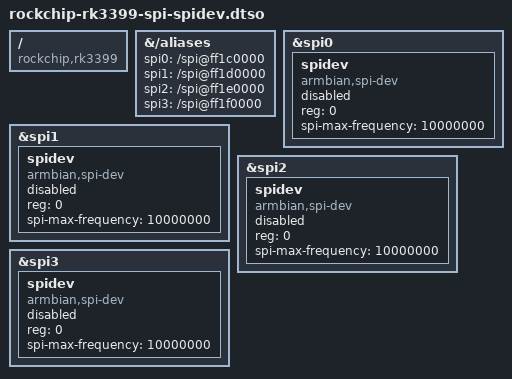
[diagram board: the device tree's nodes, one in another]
/dts-v1/;
/plugin/;

/ {
	compatible = "rockchip,rk3399";
};

&{/aliases} {
	spi0 = "/spi@ff1c0000";
	spi1 = "/spi@ff1d0000";
	spi2 = "/spi@ff1e0000";
	spi3 = "/spi@ff1f0000";
};

&spi0 {
	#address-cells = <1>;
	#size-cells = <0>;
	spidev {
		compatible = "armbian,spi-dev";
		status = "disabled";
		reg = <0>;
		spi-max-frequency = <10000000>;
	};
};

&spi1 {
	#address-cells = <1>;
	#size-cells = <0>;
	spidev {
		compatible = "armbian,spi-dev";
		status = "disabled";
		reg = <0>;
		spi-max-frequency = <10000000>;
	};
};

&spi2 {
	#address-cells = <1>;
	#size-cells = <0>;
	spidev {
		compatible = "armbian,spi-dev";
		status = "disabled";
		reg = <0>;
		spi-max-frequency = <10000000>;
	};
};

&spi3 {
	#address-cells = <1>;
	#size-cells = <0>;
	spidev {
		compatible = "armbian,spi-dev";
		status = "disabled";
		reg = <0>;
		spi-max-frequency = <10000000>;
	};
};
